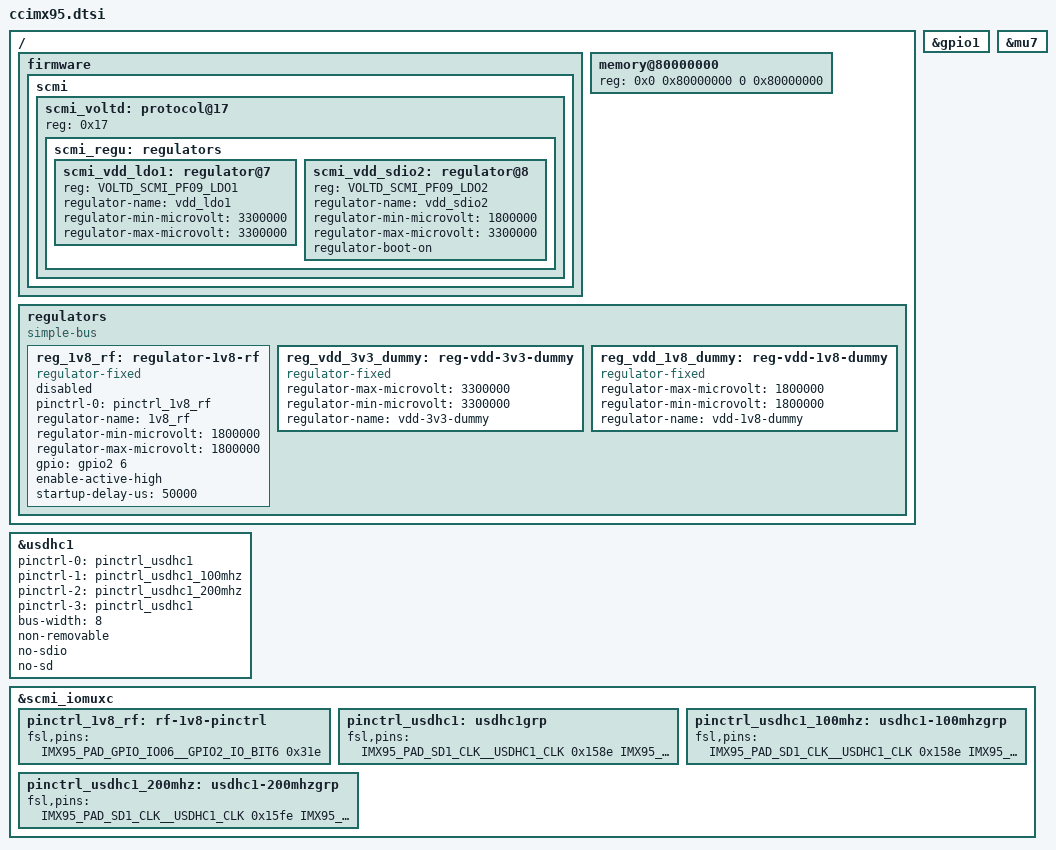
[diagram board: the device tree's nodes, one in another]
// SPDX-License-Identifier: (GPL-2.0+ OR MIT)
/*
 * Copyright 2025-2026 Digi International Inc.
 */

#include <dt-bindings/regulator/nxp,pf09-regulator.h>
#include <dt-bindings/thermal/thermal.h>

/ {
	firmware {
		scmi {
			scmi_voltd: protocol@17 {
				reg = <0x17>;

				scmi_regu: regulators {
					#address-cells = <1>;
					#size-cells = <0>;

					scmi_vdd_ldo1: regulator@7 {
						reg = <VOLTD_SCMI_PF09_LDO1>;
						regulator-name = "vdd_ldo1";
						regulator-min-microvolt = <3300000>;
						regulator-max-microvolt = <3300000>;
					};

					scmi_vdd_sdio2: regulator@8 {
						reg = <VOLTD_SCMI_PF09_LDO2>;
						regulator-name = "vdd_sdio2";
						regulator-min-microvolt = <1800000>;
						regulator-max-microvolt = <3300000>;
						regulator-boot-on;
					};
				};
			};
		};
	};

	memory@80000000 {
		device_type = "memory";
		reg = <0x0 0x80000000 0 0x80000000>;
	};

	regulators {
		compatible = "simple-bus";
		#address-cells = <1>;
		#size-cells = <0>;

		/* Wi-Fi 1v8 */
		reg_1v8_rf: regulator-1v8-rf {
			compatible = "regulator-fixed";
			pinctrl-names = "default";
			pinctrl-0 = <&pinctrl_1v8_rf>;
			regulator-name = "1v8_rf";
			regulator-min-microvolt = <1800000>;
			regulator-max-microvolt = <1800000>;
			gpio = <&gpio2 6 GPIO_ACTIVE_HIGH>; /* RF_EN */
			enable-active-high;
			startup-delay-us = <50000>;
			status = "disabled";
		};

		/*
		 * Dummy regulators to satisfy drivers supplies.
		 * These should really be the PMIC's regulators (via SCMI), but the
		 * current System Manager (SM) firmware is not able to:
		 * - not switch them off during a reboot sequence
		 * - switch them off during a poweroff sequence
		 */
		reg_vdd_3v3_dummy: reg-vdd-3v3-dummy {
			compatible = "regulator-fixed";
			regulator-max-microvolt = <3300000>;
			regulator-min-microvolt = <3300000>;
			regulator-name = "vdd-3v3-dummy";
		};

		reg_vdd_1v8_dummy: reg-vdd-1v8-dummy {
			compatible = "regulator-fixed";
			regulator-max-microvolt = <1800000>;
			regulator-min-microvolt = <1800000>;
			regulator-name = "vdd-1v8-dummy";
		};
	};
};

/* Enable GPIO1 to be used in Linux (not reserved by SM) */
&gpio1 {
	status = "okay";
};

/* Messaging Units for inter-processors communication */
&mu7 {
	status = "okay";
};

/* eMMC */
&usdhc1 {
	pinctrl-names = "default", "state_100mhz", "state_200mhz", "sleep";
	pinctrl-0 = <&pinctrl_usdhc1>;
	pinctrl-1 = <&pinctrl_usdhc1_100mhz>;
	pinctrl-2 = <&pinctrl_usdhc1_200mhz>;
	pinctrl-3 = <&pinctrl_usdhc1>;
	bus-width = <8>;
	non-removable;
	no-sdio;
	no-sd;
	status = "okay";
};

&scmi_iomuxc {
	/* Wi-Fi 1v8 RF_EN */
	pinctrl_1v8_rf: rf-1v8-pinctrl {
		fsl,pins = <
			/* RF_EN */
			IMX95_PAD_GPIO_IO06__GPIO2_IO_BIT6	0x31e
		>;
	};

	pinctrl_usdhc1: usdhc1grp {
		fsl,pins = <
			IMX95_PAD_SD1_CLK__USDHC1_CLK		0x158e
			IMX95_PAD_SD1_CMD__USDHC1_CMD		0x138e
			IMX95_PAD_SD1_DATA0__USDHC1_DATA0	0x138e
			IMX95_PAD_SD1_DATA1__USDHC1_DATA1	0x138e
			IMX95_PAD_SD1_DATA2__USDHC1_DATA2	0x138e
			IMX95_PAD_SD1_DATA3__USDHC1_DATA3	0x138e
			IMX95_PAD_SD1_DATA4__USDHC1_DATA4	0x138e
			IMX95_PAD_SD1_DATA5__USDHC1_DATA5	0x138e
			IMX95_PAD_SD1_DATA6__USDHC1_DATA6	0x138e
			IMX95_PAD_SD1_DATA7__USDHC1_DATA7	0x138e
			IMX95_PAD_SD1_STROBE__USDHC1_STROBE	0x158e
		>;
	};

	pinctrl_usdhc1_100mhz: usdhc1-100mhzgrp {
		fsl,pins = <
			IMX95_PAD_SD1_CLK__USDHC1_CLK		0x158e
			IMX95_PAD_SD1_CMD__USDHC1_CMD		0x138e
			IMX95_PAD_SD1_DATA0__USDHC1_DATA0	0x138e
			IMX95_PAD_SD1_DATA1__USDHC1_DATA1	0x138e
			IMX95_PAD_SD1_DATA2__USDHC1_DATA2	0x138e
			IMX95_PAD_SD1_DATA3__USDHC1_DATA3	0x138e
			IMX95_PAD_SD1_DATA4__USDHC1_DATA4	0x138e
			IMX95_PAD_SD1_DATA5__USDHC1_DATA5	0x138e
			IMX95_PAD_SD1_DATA6__USDHC1_DATA6	0x138e
			IMX95_PAD_SD1_DATA7__USDHC1_DATA7	0x138e
			IMX95_PAD_SD1_STROBE__USDHC1_STROBE	0x158e
		>;
	};

	pinctrl_usdhc1_200mhz: usdhc1-200mhzgrp {
		fsl,pins = <
			IMX95_PAD_SD1_CLK__USDHC1_CLK		0x15fe
			IMX95_PAD_SD1_CMD__USDHC1_CMD		0x13fe
			IMX95_PAD_SD1_DATA0__USDHC1_DATA0	0x13fe
			IMX95_PAD_SD1_DATA1__USDHC1_DATA1	0x13fe
			IMX95_PAD_SD1_DATA2__USDHC1_DATA2	0x13fe
			IMX95_PAD_SD1_DATA3__USDHC1_DATA3	0x13fe
			IMX95_PAD_SD1_DATA4__USDHC1_DATA4	0x13fe
			IMX95_PAD_SD1_DATA5__USDHC1_DATA5	0x13fe
			IMX95_PAD_SD1_DATA6__USDHC1_DATA6	0x13fe
			IMX95_PAD_SD1_DATA7__USDHC1_DATA7	0x13fe
			IMX95_PAD_SD1_STROBE__USDHC1_STROBE	0x15fe
		>;
	};
};
